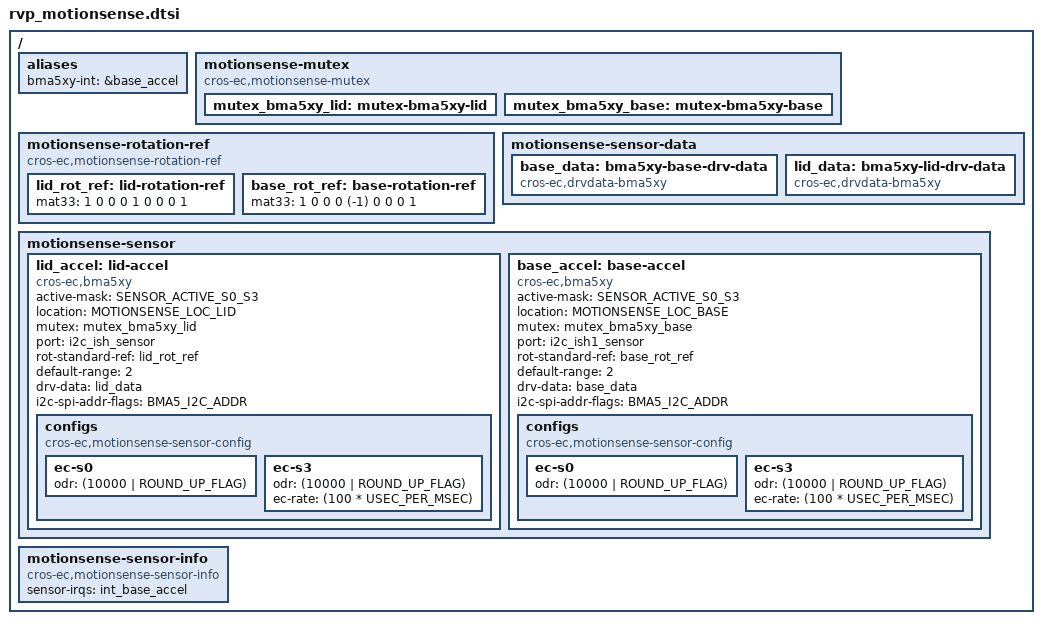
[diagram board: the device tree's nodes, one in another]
/* Copyright 2025 The ChromiumOS Authors
 * Use of this source code is governed by a BSD-style license that can be
 * found in the LICENSE file.
 */

#include <dt-bindings/motionsense/utils.h>

/ {
	aliases {
		/*
		 * motion sense's <>_INT_EVENT is handled by alias. Using the
		 * alias, each driver creates its own <>_INT_EVENT.
		 */
		bma5xy-int = &base_accel;
	};

	motionsense-mutex {
		compatible = "cros-ec,motionsense-mutex";
		mutex_bma5xy_lid: mutex-bma5xy-lid {
		};
		mutex_bma5xy_base: mutex-bma5xy-base {
		};
	};

	/* Rotation matrix used by drivers. */
	motionsense-rotation-ref {
		compatible = "cros-ec,motionsense-rotation-ref";
		lid_rot_ref: lid-rotation-ref {
			mat33 = <1 0 0
				 0 1 0
				 0 0 1>;
		};
		base_rot_ref: base-rotation-ref {
			mat33 = <1 0 0
				 0 (-1) 0
				 0 0 1>;
		};
	};

	/* Driver specific data */
	motionsense-sensor-data {
		base_data: bma5xy-base-drv-data {
			compatible = "cros-ec,drvdata-bma5xy";
			status = "okay";
		};
		lid_data: bma5xy-lid-drv-data {
			compatible = "cros-ec,drvdata-bma5xy";
			status = "okay";
		};
	};

	/* List of motion sensors that create motion_sensors array. */
	motionsense-sensor {
		lid_accel: lid-accel {
			compatible = "cros-ec,bma5xy";
			status = "okay";

			active-mask = "SENSOR_ACTIVE_S0_S3";
			location = "MOTIONSENSE_LOC_LID";
			mutex = <&mutex_bma5xy_lid>;
			port = <&i2c_ish_sensor>;
			rot-standard-ref = <&lid_rot_ref>;
			default-range = <2>;
			drv-data = <&lid_data>;
			i2c-spi-addr-flags = "BMA5_I2C_ADDR";
			configs {
				compatible =
					"cros-ec,motionsense-sensor-config";
				ec-s0 {
					odr = <(10000 | ROUND_UP_FLAG)>;
				};
				ec-s3 {
					odr = <(10000 | ROUND_UP_FLAG)>;
					ec-rate = <(100 * USEC_PER_MSEC)>;
				};
			};
		};

		base_accel: base-accel {
			compatible = "cros-ec,bma5xy";
			status = "okay";

			active-mask = "SENSOR_ACTIVE_S0_S3";
			location = "MOTIONSENSE_LOC_BASE";
			mutex = <&mutex_bma5xy_base>;
			port = <&i2c_ish1_sensor>;
			rot-standard-ref = <&base_rot_ref>;
			default-range = <2>;
			drv-data = <&base_data>;
			i2c-spi-addr-flags = "BMA5_I2C_ADDR";
			configs {
				compatible =
					"cros-ec,motionsense-sensor-config";
				ec-s0 {
					odr = <(10000 | ROUND_UP_FLAG)>;
				};
				ec-s3 {
					odr = <(10000 | ROUND_UP_FLAG)>;
					ec-rate = <(100 * USEC_PER_MSEC)>;
				};
			};
		};
	};

	/* High level description info */
	motionsense-sensor-info {
		compatible = "cros-ec,motionsense-sensor-info";
		sensor-irqs = <&int_base_accel>;
	};
};
